# cslr_timerc5501_001 register map
Vendor: Texas Instruments
Peripheral module from a debugger description file.
Registers are 16-bit, read-write, reset 0x0 unless marked. A register's access mark holds for its fields unless they carry their own. Offsets are as the file gives them; lines under a group give offsets from that group; [hi:lo] are bit positions; {n}, {i} and the like mark numbered series; 'fields as' and 'values as' point back to an identical list; <NAME> marks a mode.

## Timer
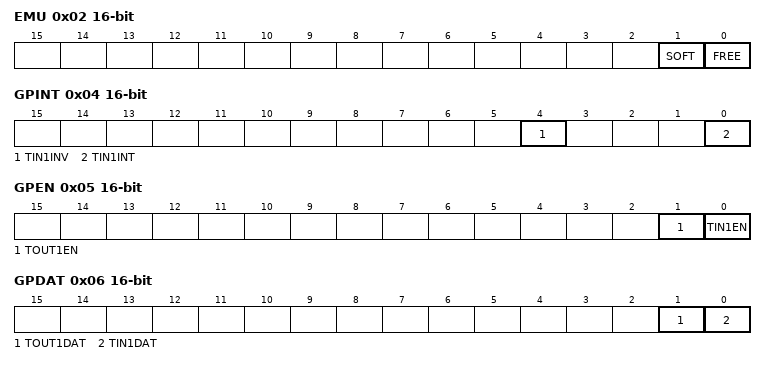
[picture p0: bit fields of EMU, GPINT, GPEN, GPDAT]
0x02 EMU access per field — Emulation Management Register
  [1] SOFT rw — Used in conjunction with FREE bit to determine how the timer responds to an emulation suspend event.
    0=The timer stops immediately; 1=The timer stops when the timer counter register increments and reaches the value in the timer period register
  [0] FREE ro — Used in conjunction with SOFT bit to determine how the timer responds to an emulation suspend event.
    0=The SOFT bit selects the timer response; 1=The timer runs free, regardless of the value of the SOFT bit
0x03 CLK access per field — Timer Clock Speed Register
  [3:0] CLKDIV ro — Clock divide-down ratio bits.
    0=Internal clock source for the timer is the fast peripherals clock (SYSCLK1); 1=1h (Internal clock source for the timer is SYSCLK1 divided by1.); 2=2h (Internal clock source for the timer is SYSCLK1 divided by 2.); 3=3h (Reserved); 4=4h (Internal clock source for the timer is SYSCLK1 divided by 4.); 8=8h (Internal clock source for the timer is SYSCLK1 divided by 8.)
0x04 GPINT — GPIO Interrupt Control Register
  [4] TIN1INV — Timer input 1 invert enable bit.
    0=Noninverted (rising) timer input 1 signal generates a timer interrupt or event; 1=Inverted (falling) timer input 1 signal generates a timer interrupt or event
  [0] TIN1INT — Timer input 1 interrupt enable bit.
    0=Timer sources the timer interrupt or event; 1=Timer input 1 sources the timer interrupt or event
0x05 GPEN — GPIO Enable Register
  [1] TOUT1EN — Timer output 1 enable bit in the GPIO mode.
    0=Timer output 1 (TOUT1) functions as a timer output; 1=Timer output 1 (TOUT1) functions as GPIO
  [0] TIN1EN — Timer input 1 enable bit in the GPIO mode.
    0=Timer input 1 (TIN1) functions as a timer input; 1=Timer input 1 (TIN1) functions as GPIO
0x06 GPDAT — GPIO Data Register
  [1] TOUT1DAT — Timer output 1 data bit in the GPIO mode.
    0=Drive the signal on the timer pin low; 1=Drive the signal on the timer pin high
  [0] TIN1DAT — Timer input 1 data bit in the GPIO mode.
    values as TOUT1DAT
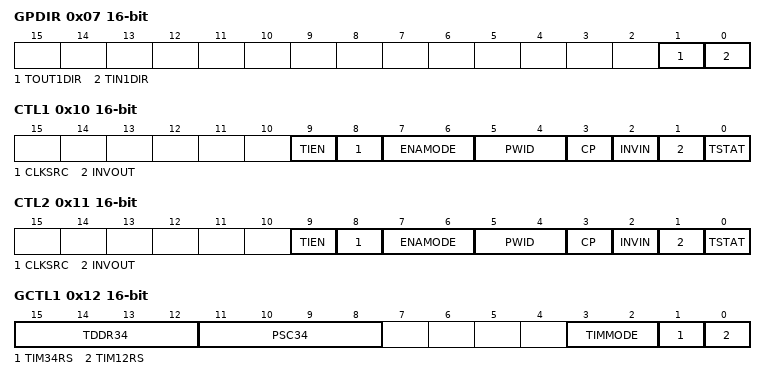
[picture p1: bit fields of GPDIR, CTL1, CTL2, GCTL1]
0x07 GPDIR — GPIO Direction Register
  [1] TOUT1DIR — Timer output 1 direction bit in the GPIO mode.
    0=The timer pin functions as a general-purpose input; 1=The timer pin functions as a general-purpose output
  [0] TIN1DIR — Timer input 1 direction bit in the GPIO mode.
    values as TOUT1DIR
{0x7+i} CNT{i} (i=1..4) — Counter Register
  [15:0] CNT{i} — Counter register.
{0xB+i} PRD{i} (i=1..4) — Period Register
  [15:0] PRD{i} — Period bits.
0x10 CTL1 access per field — Timer Control Register
  [9] TIEN rw — Timer input enable bit determines if the timer clock is gated by the timer input.
    0=Timer clock is not gated by the timer input; 1=Timer clock is gated by a high state of the timer input synchronized with the internal clock
  [8] CLKSRC rw — Clock source bit determines the clock source for the timer.
    0=The clock source is the internal clock; 1=The clock source is the signal on the timer pin
  [7:6] ENAMODE rw — Enabling mode bits determine the timer mode.
    0=The timer is disabled (not counting) and maintains the current value; 1=The timer is enabled one time; 2=The timer is enabled continuously
  [5:4] PWID rw — Pulse width bits.
    0=The pulse width is 1 timer clock cycle; 1=The pulse width is 2 timer clock cycles; 2=The pulse width is 3 timer clock cycles; 3=The pulse width is 4 timer clock cycles
  [3] CP rw — Clock/pulse mode bit for timer output.
    0=Pulse mode; 1=Clock mode
  [2] INVIN rw — Timer input inverter control bit.
    0=A noninverted timer input drives the timer; 1=An inverted timer input drives the timer
  [1] INVOUT rw — Timer output inverter control bit.
    0=The timer output is not inverted; 1=The timer output is inverted
  [0] TSTAT ro — Timer status bit.
    0=Timer output is low; 1=Timer output is high
0x11 CTL2 access per field — Timer Control Register
  fields as CTL1
0x12 GCTL1 — Global Timer Control Register 1
  [15:12] TDDR34 — Timer divide-down ratio bits.
  [11:8] PSC34 — Prescale period bits.
  [3:2] TIMMODE — Timer mode bits determine the timer operating mode.
    0=The timer is in the 64-bit general-purpose timer mode; 1=The timer is in the dual 32-bit timers unchained mode; 2=The timer is in the 64-bit watchdog timer mode; 3=The timer is in the dual 32-bit timers chained mode
  [1] TIM34RS — Timer 3:4 reset bit.
    0=Timer 3:4 is in reset; 1=Timer 3:4 is not in reset
  [0] TIM12RS — Timer 1:2 reset bit.
    0=Timer 1:2 is in reset; 1=Timer 1:2 is not in reset
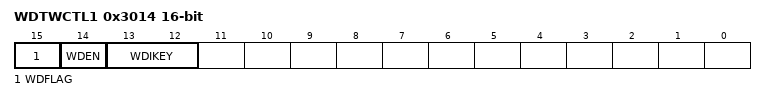
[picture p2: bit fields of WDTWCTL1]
0x3014 WDTWCTL1 — Watchdog Timer Control Register 1
  [15] WDFLAG — Watchdog timer flag bit.
    0=No watchdog timer timeout event occurred; 1=Watchdog timer timeout event occurred
  [14] WDEN — Watchdog timer enable bit.
    0=Watchdog timer is disabled; 1=Watchdog timer is enabled
  [13:12] WDIKEY — Watchdog idle enable key bits.
0x3015 WDTWCTL2 — Watchdog Timer Control Register 2
  [15:0] WDKEY — Watchdog timer service key bits.
